# nrf54l15_enga_application register map
Vendor: Nordic Semiconductor; Series: nrf54l; File version: 1
CPU: CM33 r0p4, little endian, MPU, FPU, 3 interrupt priority bits, 270 interrupts, 4 SAU regions
Registers are 32-bit, read-write, reset 0x0 unless marked. A register's access mark holds for its fields unless they carry their own. Offsets are from the block's base; [hi:lo] are bit positions; lines under a group give offsets from that group; {n}, {i} and the like mark numbered series; 'fields as' and 'values as' point back to an identical list.

## GLOBAL_CCM00_NS — AES CCM Mode Encryption 0
Base 0x40046000; alternate view of GLOBAL_AAR00_NS
Same registers: GLOBAL_CCM00_S 0x50046000 (alternate view of GLOBAL_AAR00_S)
0x00 TASKS_START wo — Start encryption/decryption. This operation will stop by itself when completed.
  [0] TASKS_START
    1=Trigger task
0x04 TASKS_STOP wo — Stop encryption/decryption
  [0] TASKS_STOP
    1=Trigger task
0x08 TASKS_RATEOVERRIDE wo — Override DATARATE setting in MODE register with the contents of the RATEOVERRIDE register for any ongoing encryption/decryption
  [0] TASKS_RATEOVERRIDE
    1=Trigger task
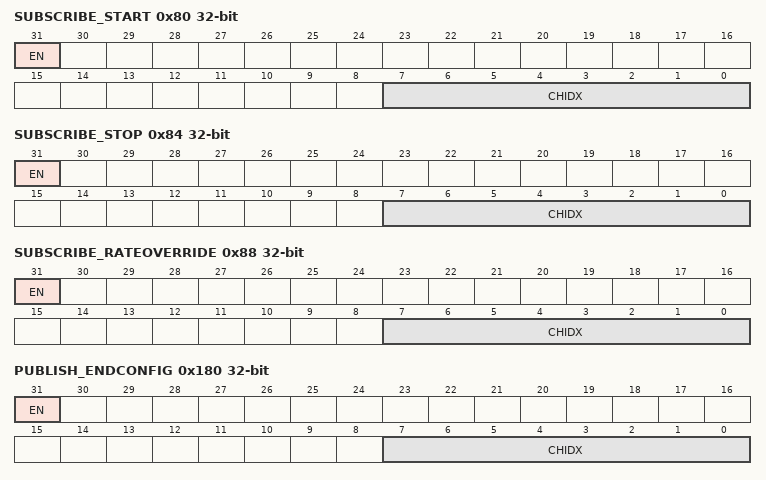
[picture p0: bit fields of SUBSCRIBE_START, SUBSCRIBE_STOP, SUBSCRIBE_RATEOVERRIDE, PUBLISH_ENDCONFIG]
0x80 SUBSCRIBE_START — Subscribe configuration for task START
  [31] EN
    0=Disabled (Disable subscription); 1=Enabled (Enable subscription)
  [7:0] CHIDX — DPPI channel that task START will subscribe to
0x84 SUBSCRIBE_STOP — Subscribe configuration for task STOP
  [31] EN
    values as SUBSCRIBE_START.EN
  [7:0] CHIDX — DPPI channel that task STOP will subscribe to
0x88 SUBSCRIBE_RATEOVERRIDE — Subscribe configuration for task RATEOVERRIDE
  [31] EN
    values as SUBSCRIBE_START.EN
  [7:0] CHIDX — DPPI channel that task RATEOVERRIDE will subscribe to
0x100 EVENTS_ENDCONFIG — Configuration data has been loaded
  [0] EVENTS_ENDCONFIG
    0=NotGenerated (Event not generated); 1=Generated (Event generated)
0x104 EVENTS_END — Encrypt/decrypt complete or ended because of an error
  [0] EVENTS_END
    values as EVENTS_ENDCONFIG.EVENTS_ENDCONFIG
0x108 EVENTS_ERROR — CCM error event
  [0] EVENTS_ERROR
    values as EVENTS_ENDCONFIG.EVENTS_ENDCONFIG
0x180 PUBLISH_ENDCONFIG — Publish configuration for event ENDCONFIG
  [31] EN
    0=Disabled (Disable publishing); 1=Enabled (Enable publishing)
  [7:0] CHIDX — DPPI channel that event ENDCONFIG will publish to
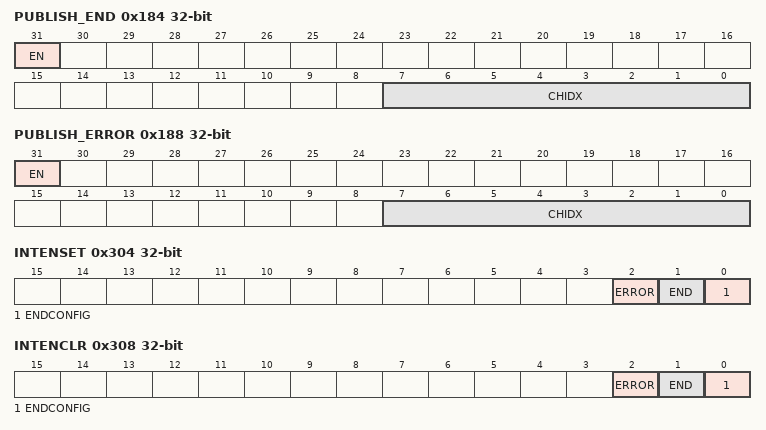
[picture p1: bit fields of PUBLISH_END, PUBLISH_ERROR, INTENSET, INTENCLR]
0x184 PUBLISH_END — Publish configuration for event END
  [31] EN
    values as PUBLISH_ENDCONFIG.EN
  [7:0] CHIDX — DPPI channel that event END will publish to
0x188 PUBLISH_ERROR — Publish configuration for event ERROR
  [31] EN
    values as PUBLISH_ENDCONFIG.EN
  [7:0] CHIDX — DPPI channel that event ERROR will publish to
0x304 INTENSET — Enable interrupt
  [all] fields
    on read: 0=Disabled (Read: Disabled); 1=Enabled (Read: Enabled) | on write: 1=Set (Enable)
  [2] ERROR — Write '1' to enable interrupt for event ERROR
  [1] END — Write '1' to enable interrupt for event END
  [0] ENDCONFIG — Write '1' to enable interrupt for event ENDCONFIG
0x308 INTENCLR — Disable interrupt
  [all] fields
    on read: 0=Disabled (Read: Disabled); 1=Enabled (Read: Enabled) | on write: 1=Clear (Disable)
  [2] ERROR — Write '1' to disable interrupt for event ERROR
  [1] END — Write '1' to disable interrupt for event END
  [0] ENDCONFIG — Write '1' to disable interrupt for event ENDCONFIG
0x400 MACSTATUS ro — MAC check result
  [0] MACSTATUS — The result of the MAC check performed during the previous decryption operation
    0=CheckFailed (MAC check failed); 1=CheckPassed (MAC check passed)
0x404 ERRORSTATUS ro
  [2:0] ERRORSTATUS — Error status when the ERROR event is generated
    0=No errors have occurred; 1=PrematureInptrEnd (End of INPTR job list before CCM data structure was read.); 2=PrematureOutptrEnd (End of OUTPTR job list before CCM data structure was read.); 3=EncryptionTooSlow (Encryption of the unencrypted CCM data structure did not complete in time.); 4=DmaError (Bus error during DMA access.)
0x500 ENABLE
  [1:0] ENABLE — Enable or disable CCM
    0=Disabled; 2=Enabled
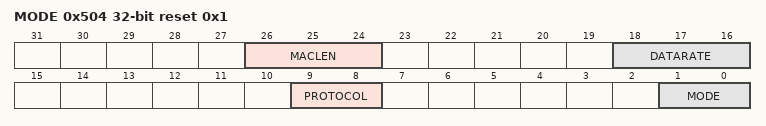
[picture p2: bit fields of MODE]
0x504 MODE reset 0x1 — Operation mode
  [26:24] MACLEN — CCM MAC length (bytes)
    0=M0 (M = 0 This is a special case for CCM* where encryption is required but not authentication); 1=M4; 2=M6; 3=M8; 4=M10; 5=M12; 6=M14; 7=M16
  [18:16] DATARATE — Radio data rate that the CCM shall run synchronous with
    0=125Kbit (125 Kbps); 1=250Kbit (250 Kbps); 2=500Kbit (500 Kbps); 3=1Mbit (1 Mbps); 4=2Mbit (2 Mbps); 5=4Mbit (4 Mbps)
  [9:8] PROTOCOL — Protocol and packet format selection
    0=Ble (Bluetooth Low Energy packet format); 1=Ieee802154 (802.15.4 packet format)
  [1:0] MODE — The mode of operation to be used. The settings in this register apply when the CRYPT task is triggered.
    0=Encryption (AES CCM packet encryption mode); 1=Decryption (AES CCM packet decryption mode); 2=FastDecryption (AES fast decrypt mode. This mode will run CCM decryption as fast as possible, i.e. not locked to a radio data rate. This can be used when a packet has been completely received.)
0x510 KEY group — Unspecified
  {0x0+4j} VALUE[{j}] (j=0..3) wo — Description collection: 128-bit AES key
    [31:0] VALUE — AES 128-bit key value, bits (32*(i+1))-1 : (32*i)
0x520 NONCE group — Unspecified
  {0x0+4j} VALUE[{j}] (j=0..3) — Description collection: 13-byte NONCE vector Only the lower 13 bytes are used
    [31:0] VALUE — NONCE value, bits (32*(n+1))-1 : (32*n)
0x530 IN group — IN EasyDMA channel
  0x00 PTR — Input pointer Points to a job list containing unencrypted CCM data structure in Encryption mode Points to a job list containing encrypted CCM data structure in Decryption mode
    [31:0] PTR — Input pointer
0x538 OUT group — OUT EasyDMA channel
  0x00 PTR — Output pointer Points to a job list containing encrypted CCM data structure in Encryption mode Points to a job list containing decrypted CCM data structure in Decryption mode
    [31:0] PTR — Output pointer
0x544 RATEOVERRIDE reset 0x2 — Data rate override setting.
  [2:0] RATEOVERRIDE
    0=125Kbit (125 Kbps); 2=500Kbit (500 Kbps); 3=1Mbit (1 Mbps); 4=2Mbit (2 Mbps); 5=4Mbit (4 Mbps)
0x548 ADATAMASK reset 0xE3 — CCM adata mask.
  [7:0] ADATAMASK — CCM adata mask. The rationale for this is to support on-the-fly masking of BLE header, as per the Bluetooth Spec.

## GLOBAL_CCM10_NS — AES CCM Mode Encryption 0
Base 0x40088000; alternate view of GLOBAL_AAR10_NS
Same registers: GLOBAL_CCM10_S 0x50088000 (alternate view of GLOBAL_AAR10_S)
Registers as GLOBAL_CCM00_NS; these are added or differ:
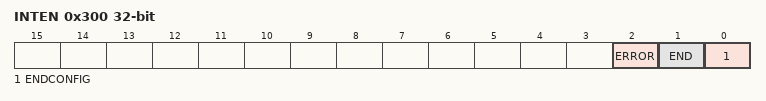
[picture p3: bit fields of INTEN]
0x300 INTEN — Enable or disable interrupt
  [all] fields
    0=Disabled; 1=Enabled
  [2] ERROR — Enable or disable interrupt for event ERROR
  [1] END — Enable or disable interrupt for event END
  [0] ENDCONFIG — Enable or disable interrupt for event ENDCONFIG

## Notices in the file
Copyright (c) 2010 - 2024, Nordic Semiconductor ASA
All rights reserved.
Redistribution and use in source and binary forms, with or without modification,
are permitted provided that the following conditions are met:
1. Redistributions of source code must retain the above copyright notice, this
list of conditions and the following disclaimer.
2. Redistributions in binary form, except as embedded into a Nordic
Semiconductor ASA integrated circuit in a product or a software update for
such product, must reproduce the above copyright notice, this list of
conditions and the following disclaimer in the documentation and/or other
materials provided with the distribution.
3. Neither the name of Nordic Semiconductor ASA nor the names of its
contributors may be used to endorse or promote products derived from this
software without specific prior written permission.
4. This software, with or without modification, must only be used with a
Nordic Semiconductor ASA integrated circuit.
5. Any software provided in binary form under this license must not be reverse
engineered, decompiled, modified and/or disassembled.
THIS SOFTWARE IS PROVIDED BY NORDIC SEMICONDUCTOR ASA "AS IS" AND ANY EXPRESS
OR IMPLIED WARRANTIES, INCLUDING, BUT NOT LIMITED TO, THE IMPLIED WARRANTIES
OF MERCHANTABILITY, NONINFRINGEMENT, AND FITNESS FOR A PARTICULAR PURPOSE ARE
DISCLAIMED. IN NO EVENT SHALL NORDIC SEMICONDUCTOR ASA OR CONTRIBUTORS BE
LIABLE FOR ANY DIRECT, INDIRECT, INCIDENTAL, SPECIAL, EXEMPLARY, OR
CONSEQUENTIAL DAMAGES (INCLUDING, BUT NOT LIMITED TO, PROCUREMENT OF SUBSTITUTE
GOODS OR SERVICES; LOSS OF USE, DATA, OR PROFITS; OR BUSINESS INTERRUPTION)
HOWEVER CAUSED AND ON ANY THEORY OF LIABILITY, WHETHER IN CONTRACT, STRICT
LIABILITY, OR TORT (INCLUDING NEGLIGENCE OR OTHERWISE) ARISING IN ANY WAY OUT
OF THE USE OF THIS SOFTWARE, EVEN IF ADVISED OF THE POSSIBILITY OF SUCH DAMAGE.
